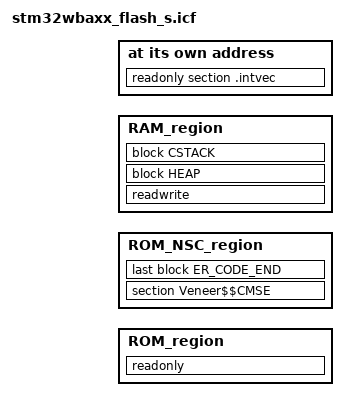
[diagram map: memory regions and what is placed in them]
/*###ICF### Section handled by ICF editor, don't touch! ****/
/*-Editor annotation file-*/
/* IcfEditorFile="$TOOLKIT_DIR$\config\ide\IcfEditor\cortex_v1_0.xml" */
/*-Specials-*/
/*************************************************************************************************/
#include "loader_region_defs.h"
/*************************************************************************************************/

define symbol __ICFEDIT_intvec_start__ = S_CODE_START;
/*-Memory Regions-*/
define symbol __ICFEDIT_region_ROM_start__ = LOADER_S_CODE_START;
define symbol __ICFEDIT_region_ROM_end__   = (LOADER_S_CODE_START + LOADER_S_CODE_SIZE -1);
define symbol __ICFEDIT_region_RAM_start__ = LOADER_S_DATA_START;
define symbol __ICFEDIT_region_RAM_end__   = (LOADER_S_DATA_START + LOADER_S_DATA_SIZE - 1);

/*-Sizes-*/
define symbol __ICFEDIT_size_cstack__ = LOADER_S_MSP_STACK_SIZE;
define symbol __ICFEDIT_size_heap__ = LOADER_S_HEAP_SIZE;
/**** End of ICF editor section. ###ICF###*/

define symbol __region_ROM_NSC_start__   = NSC_LOADER_START;
define symbol __region_ROM_NSC_end__     = (LOADER_S_ROM_ALIAS(FLASH_AREA_LOADER_OFFSET + LOADER_IMAGE_S_CODE_SIZE - 1));
define symbol __region_SRAM1_start__     = 0;
define symbol __region_SRAM1_end__       = 0;
define symbol __region_SRAM2_start__     = (LOADER_S_CODE_START + LOADER_S_CODE_SIZE -1);
define symbol __region_SRAM2_end__       = (LOADER_S_DATA_START + LOADER_S_DATA_SIZE - 1);


define memory mem with size = 4G;
define region ROM_region      = mem:[from __ICFEDIT_region_ROM_start__      to __ICFEDIT_region_ROM_end__];
define region ROM_NSC_region  = mem:[from __region_ROM_NSC_start__          to __region_ROM_NSC_end__];
define region RAM_region      = mem:[from __ICFEDIT_region_RAM_start__      to __ICFEDIT_region_RAM_end__];
define region SRAM1_region    = mem:[from __region_SRAM1_start__   to __region_SRAM1_end__];
define region SRAM2_region    = mem:[from __region_SRAM2_start__   to __region_SRAM2_end__];

define block CSTACK    with alignment = 8, size = __ICFEDIT_size_cstack__   { };
define block HEAP      with alignment = 8, size = __ICFEDIT_size_heap__     { };
define block ER_CODE_END with alignment = 2, size =  0{ };

initialize by copy { readwrite };

place at address mem:__ICFEDIT_intvec_start__ { readonly section .intvec };

place in ROM_region     { readonly };
place in ROM_NSC_region { section Veneer$$CMSE ,last block ER_CODE_END};
place in RAM_region     { readwrite, block HEAP, block CSTACK,   };
place in SRAM1_region   { };
place in SRAM2_region   { };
